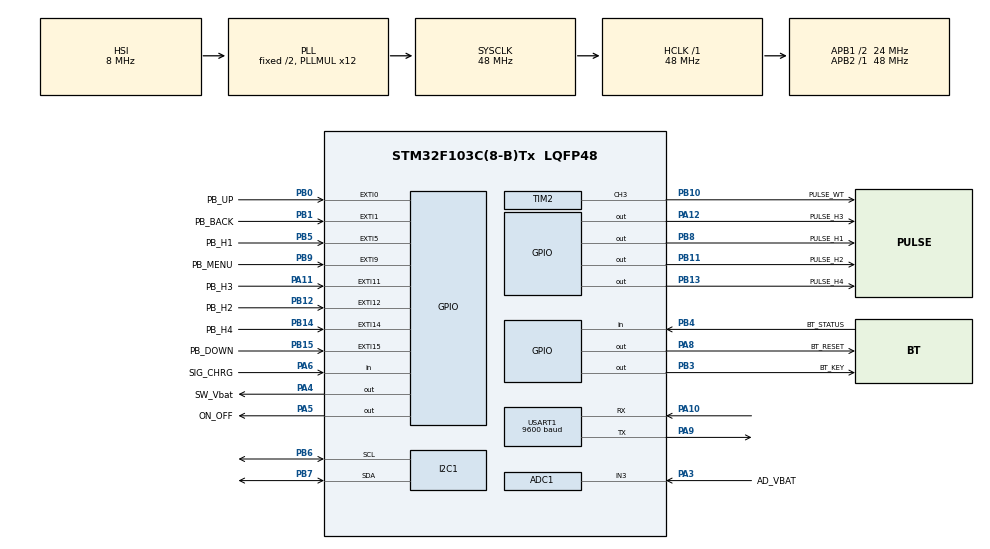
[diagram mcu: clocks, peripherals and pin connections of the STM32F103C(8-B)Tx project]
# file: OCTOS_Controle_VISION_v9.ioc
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ADC1.Channel-0\#ChannelRegularConversion=ADC_CHANNEL_3
ADC1.ContinuousConvMode=ENABLE
ADC1.NbrOfConversionFlag=1
ADC1.Rank-0\#ChannelRegularConversion=1
ADC1.SamplingTime-0\#ChannelRegularConversion=ADC_SAMPLETIME_239CYCLES_5
ADC1.master=1
Dma.ADC1.1.Direction=DMA_PERIPH_TO_MEMORY
Dma.ADC1.1.Instance=DMA1_Channel1
Dma.ADC1.1.MemDataAlignment=DMA_MDATAALIGN_WORD
Dma.ADC1.1.MemInc=DMA_MINC_ENABLE
Dma.ADC1.1.Mode=DMA_CIRCULAR
Dma.ADC1.1.PeriphDataAlignment=DMA_PDATAALIGN_WORD
Dma.ADC1.1.PeriphInc=DMA_PINC_DISABLE
Dma.ADC1.1.Priority=DMA_PRIORITY_LOW
Dma.Request0=USART1_RX
Dma.Request1=ADC1
Dma.USART1_RX.0.Direction=DMA_PERIPH_TO_MEMORY
Dma.USART1_RX.0.Instance=DMA1_Channel5
Dma.USART1_RX.0.MemDataAlignment=DMA_MDATAALIGN_BYTE
Dma.USART1_RX.0.MemInc=DMA_MINC_ENABLE
Dma.USART1_RX.0.Mode=DMA_NORMAL
Dma.USART1_RX.0.PeriphDataAlignment=DMA_PDATAALIGN_BYTE
Dma.USART1_RX.0.PeriphInc=DMA_PINC_DISABLE
Dma.USART1_RX.0.Priority=DMA_PRIORITY_LOW
Mcu.Family=STM32F1
Mcu.Name=STM32F103C(8-B)Tx
Mcu.Package=LQFP48
NVIC.DMA1_Channel1_IRQn=true\:1\:0\:true\:false\:true\:false\:true\:true
NVIC.DMA1_Channel5_IRQn=true\:1\:0\:true\:false\:true\:false\:true\:true
NVIC.EXTI0_IRQn=true\:3\:0\:true\:false\:true\:true\:true\:true
NVIC.EXTI15_10_IRQn=true\:3\:0\:true\:false\:true\:true\:true\:true
NVIC.EXTI1_IRQn=true\:3\:0\:true\:false\:true\:true\:true\:true
NVIC.EXTI9_5_IRQn=true\:3\:0\:true\:false\:true\:true\:true\:true
NVIC.PriorityGroup=NVIC_PRIORITYGROUP_4
NVIC.TIM2_IRQn=true\:2\:0\:true\:false\:true\:true\:true\:true
NVIC.USART1_IRQn=true\:1\:0\:true\:false\:true\:true\:true\:true
PA10.Mode=Asynchronous
PA10.Signal=USART1_RX
PA11.GPIO_Label=PB_H3
PA11.GPIO_ModeDefaultEXTI=GPIO_MODE_IT_FALLING
PA11.Signal=GPXTI11
PA12.GPIO_Label=PULSE_H3
PA12.Signal=GPIO_Output
PA13.Mode=Serial_Wire
PA13.Signal=SYS_JTMS-SWDIO
PA14.Mode=Serial_Wire
PA14.Signal=SYS_JTCK-SWCLK
PA3.GPIO_Label=AD_VBAT
PA3.Signal=ADCx_IN3
PA4.GPIO_Label=SW_Vbat
PA4.Signal=GPIO_Output
PA5.GPIO_Label=ON_OFF
PA5.GPIO_PuPd=GPIO_PULLDOWN
PA5.Signal=GPIO_Output
PA6.GPIO_Label=SIG_CHRG
PA6.Signal=GPIO_Input
PA8.GPIO_Label=BT_RESET
PA8.PinState=GPIO_PIN_SET
PA8.Signal=GPIO_Output
PA9.Mode=Asynchronous
PA9.Signal=USART1_TX
PB0.GPIO_Label=PB_UP
PB0.GPIO_ModeDefaultEXTI=GPIO_MODE_IT_FALLING
PB0.Signal=GPXTI0
PB1.GPIO_Label=PB_BACK
PB1.GPIO_ModeDefaultEXTI=GPIO_MODE_IT_FALLING
PB1.Signal=GPXTI1
PB10.GPIO_Label=PULSE_WT
PB10.Signal=S_TIM2_CH3
PB11.GPIO_Label=PULSE_H2
PB11.Signal=GPIO_Output
PB12.GPIO_Label=PB_H2
PB12.GPIO_ModeDefaultEXTI=GPIO_MODE_IT_FALLING
PB12.Signal=GPXTI12
PB13.GPIO_Label=PULSE_H4
PB13.Signal=GPIO_Output
PB14.GPIO_Label=PB_H4
PB14.GPIO_ModeDefaultEXTI=GPIO_MODE_IT_FALLING
PB14.Signal=GPXTI14
PB15.GPIO_Label=PB_DOWN
PB15.GPIO_ModeDefaultEXTI=GPIO_MODE_IT_FALLING
PB15.Signal=GPXTI15
PB3.GPIO_Label=BT_KEY
PB3.PinState=GPIO_PIN_SET
PB3.Signal=GPIO_Output
PB4.GPIO_Label=BT_STATUS
PB4.Signal=GPIO_Input
PB5.GPIO_Label=PB_H1
PB5.GPIO_ModeDefaultEXTI=GPIO_MODE_IT_FALLING
PB5.Signal=GPXTI5
PB6.Mode=I2C
PB6.Signal=I2C1_SCL
PB7.Mode=I2C
PB7.Signal=I2C1_SDA
PB8.GPIO_Label=PULSE_H1
PB8.Signal=GPIO_Output
PB9.GPIO_Label=PB_MENU
PB9.GPIO_ModeDefaultEXTI=GPIO_MODE_IT_FALLING
PB9.Signal=GPXTI9
ProjectManager.HeapSize=0x200
ProjectManager.StackSize=0x400
ProjectManager.TargetToolchain=STM32CubeIDE
RCC.ADCPresc=RCC_ADCPCLK2_DIV8
RCC.AHBFreq_Value=48000000
RCC.APB1CLKDivider=RCC_HCLK_DIV2
RCC.APB1Freq_Value=24000000
RCC.APB1TimFreq_Value=48000000
RCC.APB2Freq_Value=48000000
RCC.APB2TimFreq_Value=48000000
RCC.HCLKFreq_Value=48000000
RCC.PLLMUL=RCC_PLL_MUL12
RCC.SYSCLKFreq_VALUE=48000000
RCC.SYSCLKSource=RCC_SYSCLKSOURCE_PLLCLK
RCC.USBFreq_Value=48000000
SH.ADCx_IN3.0=ADC1_IN3,IN3
SH.S_TIM2_CH3.0=TIM2_CH3,PWM Generation3 CH3
TIM2.Channel-PWM\ Generation3\ CH3=TIM_CHANNEL_3
TIM2.Period=100-1
TIM2.Prescaler=4800-1
TIM2.Pulse-PWM\ Generation3\ CH3=50
USART1.BaudRate=9600
USART1.VirtualMode=VM_ASYNC
board=custom

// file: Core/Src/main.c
/* USER CODE BEGIN Header */
/**
  ******************************************************************************
  * @file           : main.c
  * @brief          : Main program body
  ******************************************************************************
  * @attention
  *
  * Copyright (c) 2023 STMicroelectronics.
  * All rights reserved.
  *
  * This software is licensed under terms that can be found in the LICENSE file
  * in the root directory of this software component.
  * If no LICENSE file comes with this software, it is provided AS-IS.
  *
  ******************************************************************************
  */
/* USER CODE END Header */
#include "main.h"
#include "adc.h"
#include "dma.h"
#include "i2c.h"
#include "tim.h"
#include "usart.h"
#include "gpio.h"

/* USER CODE BEGIN Includes */
#include "u8g_com_arm_stm32.h" 	//INCLUDE DISPLAY
/* USER CODE END Includes */

void SystemClock_Config(void);

int main(void)
{

  /* MCU Configuration--------------------------------------------------------*/

  /* Reset of all peripherals, Initializes the Flash interface and the Systick. */
  HAL_Init();

  /* Configure the system clock */
  SystemClock_Config();

  /* Initialize all configured peripherals */
  MX_GPIO_Init();
  MX_DMA_Init();
  MX_ADC1_Init();
  MX_I2C1_Init();
  MX_TIM2_Init();
  MX_USART1_UART_Init();

  /* Infinite loop */
  while (1)
  {

  }
}

void SystemClock_Config(void)
{
  RCC_OscInitTypeDef RCC_OscInitStruct = {0};
  RCC_ClkInitTypeDef RCC_ClkInitStruct = {0};
  RCC_PeriphCLKInitTypeDef PeriphClkInit = {0};

  /** Initializes the RCC Oscillators according to the specified parameters
  * in the RCC_OscInitTypeDef structure.
  */
  RCC_OscInitStruct.OscillatorType = RCC_OSCILLATORTYPE_HSI;
  RCC_OscInitStruct.HSIState = RCC_HSI_ON;
  RCC_OscInitStruct.HSICalibrationValue = RCC_HSICALIBRATION_DEFAULT;
  RCC_OscInitStruct.PLL.PLLState = RCC_PLL_ON;
  RCC_OscInitStruct.PLL.PLLSource = RCC_PLLSOURCE_HSI_DIV2;
  RCC_OscInitStruct.PLL.PLLMUL = RCC_PLL_MUL12;
  if (HAL_RCC_OscConfig(&RCC_OscInitStruct) != HAL_OK)
  {
    Error_Handler();
  }

  /** Initializes the CPU, AHB and APB buses clocks
  */
  RCC_ClkInitStruct.ClockType = RCC_CLOCKTYPE_HCLK|RCC_CLOCKTYPE_SYSCLK
                              |RCC_CLOCKTYPE_PCLK1|RCC_CLOCKTYPE_PCLK2;
  RCC_ClkInitStruct.SYSCLKSource = RCC_SYSCLKSOURCE_PLLCLK;
  RCC_ClkInitStruct.AHBCLKDivider = RCC_SYSCLK_DIV1;
  RCC_ClkInitStruct.APB1CLKDivider = RCC_HCLK_DIV2;
  RCC_ClkInitStruct.APB2CLKDivider = RCC_HCLK_DIV1;

  if (HAL_RCC_ClockConfig(&RCC_ClkInitStruct, FLASH_LATENCY_1) != HAL_OK)
  {
    Error_Handler();
  }
  PeriphClkInit.PeriphClockSelection = RCC_PERIPHCLK_ADC;
  PeriphClkInit.AdcClockSelection = RCC_ADCPCLK2_DIV8;
  if (HAL_RCCEx_PeriphCLKConfig(&PeriphClkInit) != HAL_OK)
  {
    Error_Handler();
  }
}

void Error_Handler(void)
{
  __disable_irq();
  while (1)
  {
  }
}
